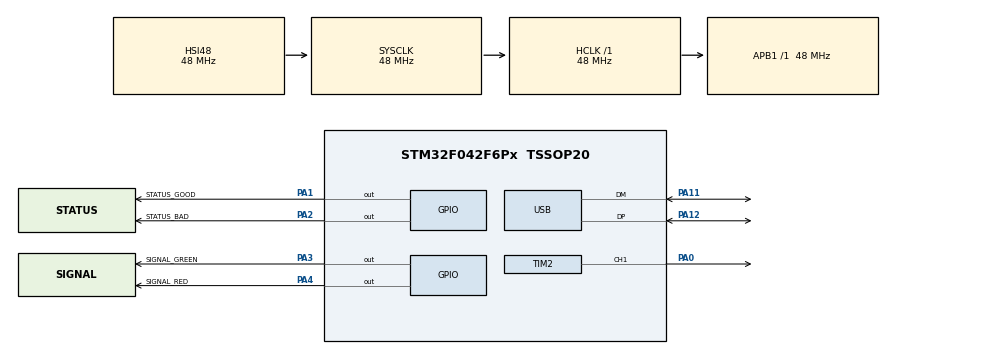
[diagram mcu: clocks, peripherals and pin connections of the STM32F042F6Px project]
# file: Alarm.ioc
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Mcu.Family=STM32F0
Mcu.Name=STM32F042F6Px
Mcu.Package=TSSOP20
NVIC.USB_IRQn=true\:0\:0\:false\:false\:true\:false\:true\:true
PA0.Signal=S_TIM2_CH1_ETR
PA1.GPIO_Label=STATUS_GOOD
PA1.Signal=GPIO_Output
PA11.Mode=Device
PA11.Signal=USB_DM
PA12.Mode=Device
PA12.Signal=USB_DP
PA13.Mode=Serial_Wire
PA13.Signal=SYS_SWDIO
PA14.Mode=Serial_Wire
PA14.Signal=SYS_SWCLK
PA2.GPIO_Label=STATUS_BAD
PA2.Signal=GPIO_Output
PA3.GPIO_Label=SIGNAL_GREEN
PA3.Signal=GPIO_Output
PA4.GPIO_Label=SIGNAL_RED
PA4.Signal=GPIO_Output
ProjectManager.HeapSize=0x200
ProjectManager.StackSize=0x400
ProjectManager.TargetToolchain=STM32CubeIDE
RCC.AHBFreq_Value=48000000
RCC.APB1Freq_Value=48000000
RCC.APB1TimFreq_Value=48000000
RCC.HCLKFreq_Value=48000000
RCC.SYSCLKFreq_VALUE=48000000
RCC.SYSCLKSource=RCC_SYSCLKSOURCE_HSI48
SH.S_TIM2_CH1_ETR.0=TIM2_CH1,PWM Generation1 CH1
TIM1.Prescaler=47999
TIM2.Channel-PWM\ Generation1\ CH1=TIM_CHANNEL_1
TIM2.Period=1249
TIM2.Prescaler=47
TIM2.Pulse-PWM\ Generation1\ CH1=624
TIM3.Period=999
TIM3.Prescaler=47999
USB_DEVICE.APP_RX_DATA_SIZE=64
USB_DEVICE.APP_TX_DATA_SIZE=64
USB_DEVICE.CLASS_NAME_FS=CDC
USB_DEVICE.MANUFACTURER_STRING=H-BRS/ISF
USB_DEVICE.PRODUCT_STRING_CDC_FS=ReDeX Alarm
USB_DEVICE.USBD_MAX_STR_DESC_SIZ=128
USB_DEVICE.USBD_SELF_POWERED=0
USB_DEVICE.VirtualMode=Cdc
USB_DEVICE.VirtualModeFS=Cdc_FS
VP_SYS_VS_PINREMAP.Mode=PINREMAP
VP_TIM1_VS_ClockSourceINT.Mode=Internal
VP_TIM2_VS_ClockSourceINT.Mode=Internal
VP_TIM3_VS_ClockSourceINT.Mode=Internal
VP_USB_DEVICE_VS_USB_DEVICE_CDC_FS.Mode=CDC_FS
board=custom

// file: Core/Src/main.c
/* USER CODE BEGIN Header */
/**
  ******************************************************************************
  * @file           : main.c
  * @brief          : Main program body
  ******************************************************************************
  * @attention
  *
  * Copyright (c) 2022 STMicroelectronics.
  * All rights reserved.
  *
  * This software is licensed under terms that can be found in the LICENSE file
  * in the root directory of this software component.
  * If no LICENSE file comes with this software, it is provided AS-IS.
  *
  ******************************************************************************
  */
/* USER CODE END Header */
#include "alarm.h"
#include "main.h"
#include "usb_device.h"

TIM_HandleTypeDef htim1;
TIM_HandleTypeDef htim2;
TIM_HandleTypeDef htim3;

void SystemClock_Config(void);
static void MX_GPIO_Init(void);
static void MX_TIM2_Init(void);
static void MX_TIM1_Init(void);
static void MX_TIM3_Init(void);

int main(void)
{

  /* MCU Configuration--------------------------------------------------------*/

  /* Reset of all peripherals, Initializes the Flash interface and the Systick. */
  HAL_Init();

  /* Configure the system clock */
  SystemClock_Config();

  /* Initialize all configured peripherals */
  MX_GPIO_Init();
  MX_TIM2_Init();
  MX_USB_DEVICE_Init();
  MX_TIM1_Init();
  MX_TIM3_Init();
  /* USER CODE BEGIN 2 */
  alarm_main();
  /* USER CODE END 2 */

  /* Infinite loop */
  while (1)
  {

  }
}

void SystemClock_Config(void)
{
  RCC_OscInitTypeDef RCC_OscInitStruct = {0};
  RCC_ClkInitTypeDef RCC_ClkInitStruct = {0};
  RCC_PeriphCLKInitTypeDef PeriphClkInit = {0};

  /** Initializes the RCC Oscillators according to the specified parameters
  * in the RCC_OscInitTypeDef structure.
  */
  RCC_OscInitStruct.OscillatorType = RCC_OSCILLATORTYPE_HSI48;
  RCC_OscInitStruct.HSI48State = RCC_HSI48_ON;
  RCC_OscInitStruct.PLL.PLLState = RCC_PLL_NONE;
  if (HAL_RCC_OscConfig(&RCC_OscInitStruct) != HAL_OK)
  {
    Error_Handler();
  }

  /** Initializes the CPU, AHB and APB buses clocks
  */
  RCC_ClkInitStruct.ClockType = RCC_CLOCKTYPE_HCLK|RCC_CLOCKTYPE_SYSCLK
                              |RCC_CLOCKTYPE_PCLK1;
  RCC_ClkInitStruct.SYSCLKSource = RCC_SYSCLKSOURCE_HSI48;
  RCC_ClkInitStruct.AHBCLKDivider = RCC_SYSCLK_DIV1;
  RCC_ClkInitStruct.APB1CLKDivider = RCC_HCLK_DIV1;

  if (HAL_RCC_ClockConfig(&RCC_ClkInitStruct, FLASH_LATENCY_1) != HAL_OK)
  {
    Error_Handler();
  }
  PeriphClkInit.PeriphClockSelection = RCC_PERIPHCLK_USB;
  PeriphClkInit.UsbClockSelection = RCC_USBCLKSOURCE_HSI48;

  if (HAL_RCCEx_PeriphCLKConfig(&PeriphClkInit) != HAL_OK)
  {
    Error_Handler();
  }
}

static void MX_TIM1_Init(void)
{

  TIM_ClockConfigTypeDef sClockSourceConfig = {0};
  TIM_MasterConfigTypeDef sMasterConfig = {0};

  htim1.Instance = TIM1;
  htim1.Init.Prescaler = 47999;
  htim1.Init.CounterMode = TIM_COUNTERMODE_UP;
  htim1.Init.Period = 65535;
  htim1.Init.ClockDivision = TIM_CLOCKDIVISION_DIV1;
  htim1.Init.RepetitionCounter = 0;
  htim1.Init.AutoReloadPreload = TIM_AUTORELOAD_PRELOAD_DISABLE;
  if (HAL_TIM_Base_Init(&htim1) != HAL_OK)
  {
    Error_Handler();
  }
  sClockSourceConfig.ClockSource = TIM_CLOCKSOURCE_INTERNAL;
  if (HAL_TIM_ConfigClockSource(&htim1, &sClockSourceConfig) != HAL_OK)
  {
    Error_Handler();
  }
  sMasterConfig.MasterOutputTrigger = TIM_TRGO_RESET;
  sMasterConfig.MasterSlaveMode = TIM_MASTERSLAVEMODE_DISABLE;
  if (HAL_TIMEx_MasterConfigSynchronization(&htim1, &sMasterConfig) != HAL_OK)
  {
    Error_Handler();
  }

}

static void MX_TIM2_Init(void)
{

  TIM_ClockConfigTypeDef sClockSourceConfig = {0};
  TIM_MasterConfigTypeDef sMasterConfig = {0};
  TIM_OC_InitTypeDef sConfigOC = {0};

  htim2.Instance = TIM2;
  htim2.Init.Prescaler = 47;
  htim2.Init.CounterMode = TIM_COUNTERMODE_UP;
  htim2.Init.Period = 1249;
  htim2.Init.ClockDivision = TIM_CLOCKDIVISION_DIV1;
  htim2.Init.AutoReloadPreload = TIM_AUTORELOAD_PRELOAD_DISABLE;
  if (HAL_TIM_Base_Init(&htim2) != HAL_OK)
  {
    Error_Handler();
  }
  sClockSourceConfig.ClockSource = TIM_CLOCKSOURCE_INTERNAL;
  if (HAL_TIM_ConfigClockSource(&htim2, &sClockSourceConfig) != HAL_OK)
  {
    Error_Handler();
  }
  if (HAL_TIM_PWM_Init(&htim2) != HAL_OK)
  {
    Error_Handler();
  }
  sMasterConfig.MasterOutputTrigger = TIM_TRGO_RESET;
  sMasterConfig.MasterSlaveMode = TIM_MASTERSLAVEMODE_DISABLE;
  if (HAL_TIMEx_MasterConfigSynchronization(&htim2, &sMasterConfig) != HAL_OK)
  {
    Error_Handler();
  }
  sConfigOC.OCMode = TIM_OCMODE_PWM1;
  sConfigOC.Pulse = 624;
  sConfigOC.OCPolarity = TIM_OCPOLARITY_HIGH;
  sConfigOC.OCFastMode = TIM_OCFAST_DISABLE;
  if (HAL_TIM_PWM_ConfigChannel(&htim2, &sConfigOC, TIM_CHANNEL_1) != HAL_OK)
  {
    Error_Handler();
  }
  HAL_TIM_MspPostInit(&htim2);

}

static void MX_TIM3_Init(void)
{

  TIM_ClockConfigTypeDef sClockSourceConfig = {0};
  TIM_MasterConfigTypeDef sMasterConfig = {0};

  htim3.Instance = TIM3;
  htim3.Init.Prescaler = 47999;
  htim3.Init.CounterMode = TIM_COUNTERMODE_UP;
  htim3.Init.Period = 999;
  htim3.Init.ClockDivision = TIM_CLOCKDIVISION_DIV1;
  htim3.Init.AutoReloadPreload = TIM_AUTORELOAD_PRELOAD_DISABLE;
  if (HAL_TIM_Base_Init(&htim3) != HAL_OK)
  {
    Error_Handler();
  }
  sClockSourceConfig.ClockSource = TIM_CLOCKSOURCE_INTERNAL;
  if (HAL_TIM_ConfigClockSource(&htim3, &sClockSourceConfig) != HAL_OK)
  {
    Error_Handler();
  }
  sMasterConfig.MasterOutputTrigger = TIM_TRGO_RESET;
  sMasterConfig.MasterSlaveMode = TIM_MASTERSLAVEMODE_DISABLE;
  if (HAL_TIMEx_MasterConfigSynchronization(&htim3, &sMasterConfig) != HAL_OK)
  {
    Error_Handler();
  }

}

static void MX_GPIO_Init(void)
{
  GPIO_InitTypeDef GPIO_InitStruct = {0};

  /* GPIO Ports Clock Enable */
  __HAL_RCC_GPIOA_CLK_ENABLE();

  /*Configure GPIO pin Output Level */
  HAL_GPIO_WritePin(GPIOA, STATUS_GOOD_Pin|STATUS_BAD_Pin|SIGNAL_GREEN_Pin|SIGNAL_RED_Pin, GPIO_PIN_RESET);

  /*Configure GPIO pins : STATUS_GOOD_Pin STATUS_BAD_Pin SIGNAL_GREEN_Pin SIGNAL_RED_Pin */
  GPIO_InitStruct.Pin = STATUS_GOOD_Pin|STATUS_BAD_Pin|SIGNAL_GREEN_Pin|SIGNAL_RED_Pin;
  GPIO_InitStruct.Mode = GPIO_MODE_OUTPUT_PP;
  GPIO_InitStruct.Pull = GPIO_NOPULL;
  GPIO_InitStruct.Speed = GPIO_SPEED_FREQ_LOW;
  HAL_GPIO_Init(GPIOA, &GPIO_InitStruct);

}

void Error_Handler(void)
{
  __disable_irq();
  while (1)
  {
  }
}
